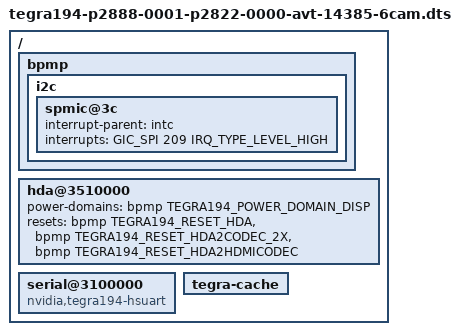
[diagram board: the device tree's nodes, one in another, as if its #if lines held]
/*
 * Top level DTS file for CVM:P2888-0001, CVB:P2822-0000 and IMX274-HDMI module.
 *
 * Copyright (c) 2017-2018, NVIDIA CORPORATION.  All rights reserved.
 *
 * This program is free software; you can redistribute it and/or modify
 * it under the terms of the GNU General Public License as published by
 * the Free Software Foundation; version 2 of the License.
 *
 * This program is distributed in the hope that it will be useful, but WITHOUT
 * ANY WARRANTY; without even the implied warranty of MERCHANTABILITY or
 * FITNESS FOR A PARTICULAR PURPOSE.  See the GNU General Public License for
 * more details.
 */

#include "common/tegra194-p2888-0001-p2822-0000-common.dtsi"
#include "common/tegra194-p2822-0000-camera-avt-csi2-14385-6cam.dtsi"
#include "common/tegra194-audio-p2822-0000.dtsi"

#if defined(LINUX_VERSION) && LINUX_VERSION >= 419

/ {
	/* FIXME: K5.4 overrides */
	bpmp {
		i2c {
			spmic@3c {
				interrupt-parent = <&intc>;
				interrupts = <GIC_SPI 209 IRQ_TYPE_LEVEL_HIGH>;
			};
		};
	};

	hda@3510000 {
		power-domains = <&bpmp TEGRA194_POWER_DOMAIN_DISP>;
		resets = <&bpmp TEGRA194_RESET_HDA>,
			 <&bpmp TEGRA194_RESET_HDA2CODEC_2X>,
			 <&bpmp TEGRA194_RESET_HDA2HDMICODEC>;
		reset-names = "hda", "hda2codec_2x", "hda2hdmi";
	};

	serial@3100000 {
		compatible = "nvidia,tegra194-hsuart";
	};

	tegra-cache {
		status = "okay";
	};
};

#endif
